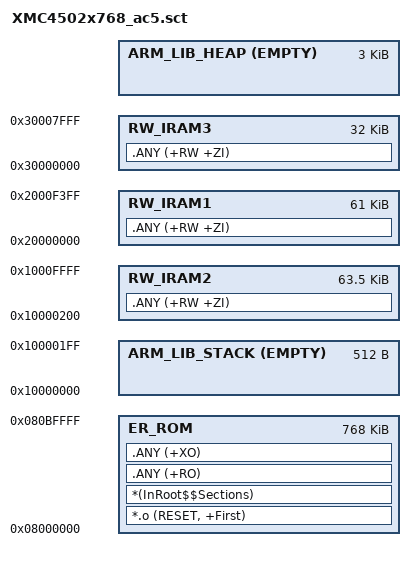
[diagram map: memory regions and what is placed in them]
#! armcc -E
; command above MUST be in first line (no comment above!)

/*
;-------- <<< Use Configuration Wizard in Context Menu >>> -------------------
*/

/*--------------------- Flash Configuration ----------------------------------
; <h> Flash Configuration
;   <o0> Flash Base Address <0x0-0xFFFFFFFF:8>
;   <o1> Flash Size (in Bytes) <0x0-0xFFFFFFFF:8>
; </h>
 *----------------------------------------------------------------------------*/
#define __ROM_BASE     0x08000000
#define __ROM_SIZE     0x000C0000

/*--------------------- Embedded RAM Configuration ---------------------------
; <h> RAM Configuration
;   <o0> RAM1 Base Address    <0x0-0xFFFFFFFF:8>
;   <o1> RAM1 Size (in Bytes) <0x0-0xFFFFFFFF:8>
;   <o2> RAM2 Base Address    <0x0-0xFFFFFFFF:8>
;   <o3> RAM2 Size (in Bytes) <0x0-0xFFFFFFFF:8>
;   <o4> RAM3 Base Address    <0x0-0xFFFFFFFF:8>
;   <o5> RAM3 Size (in Bytes) <0x0-0xFFFFFFFF:8>
; </h>
 *----------------------------------------------------------------------------*/
#define __RAM1_BASE     0x20000000
#define __RAM1_SIZE     0x00010000

#define __RAM2_BASE     0x10000000
#define __RAM2_SIZE     0x00010000

#define __RAM3_BASE     0x30000000
#define __RAM3_SIZE     0x00008000

/*--------------------- Stack / Heap Configuration ---------------------------
; <h> Stack / Heap Configuration
;   <o0> Stack Size (in Bytes) <0x0-0xFFFFFFFF:8>
;   <o1> Heap Size (in Bytes) <0x0-0xFFFFFFFF:8>
; </h>
 *----------------------------------------------------------------------------*/
#define __STACK_SIZE       0x00000200
#define __HEAP_SIZE        0x00000C00


/*----------------------------------------------------------------------------
  User Stack & Heap boundery definition
 *----------------------------------------------------------------------------*/
#define __STACK_TOP        (__RAM2_BASE + __STACK_SIZE)      /* starts at end of RAM */
#define __HEAP_BASE        (AlignExpr(+0, 8))             /* starts after RW_RAM section, 8 byte aligned */


/*----------------------------------------------------------------------------
  Scatter File Definitions definition
 *----------------------------------------------------------------------------*/
#define __RO_BASE         __ROM_BASE
#define __RO_SIZE         __ROM_SIZE

#define __RW2_BASE        (__STACK_TOP        )
#define __RW2_SIZE        (__RAM2_SIZE - __STACK_SIZE)

#define __RW1_BASE        (__RAM1_BASE        )
#define __RW1_SIZE        (__RAM1_SIZE - __HEAP_SIZE)

#define __RW3_BASE        __RAM3_BASE
#define __RW3_SIZE        __RAM3_SIZE

LR_ROM __RO_BASE __RO_SIZE  {                       ; load region size_region
  ER_ROM __RO_BASE __RO_SIZE  {                     ; load address = execution address
   *.o (RESET, +First)
   *(InRoot$$Sections)
   .ANY (+RO)
   .ANY (+XO)
  }

  ARM_LIB_STACK __STACK_TOP EMPTY -__STACK_SIZE {   ; Reserve empty region for stack
  }

  RW_IRAM2 __RW2_BASE __RW2_SIZE  {                     ; RW data
   .ANY (+RW +ZI)
  }

  RW_IRAM1 __RW1_BASE __RW1_SIZE  {                     ; RW data
   .ANY (+RW +ZI)
  }

  RW_IRAM3 __RW3_BASE __RW3_SIZE  {                     ; RW data
   .ANY (+RW +ZI)
  }

#if __HEAP_SIZE > 0
  ARM_LIB_HEAP  __HEAP_BASE EMPTY  __HEAP_SIZE  {   ; Reserve empty region for heap
  }
#endif

}

